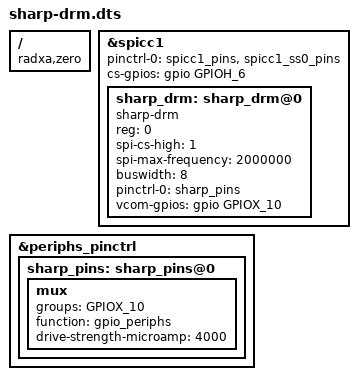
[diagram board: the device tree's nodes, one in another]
/dts-v1/;
/plugin/;

#include <dt-bindings/gpio/gpio.h>
#include <dt-bindings/gpio/meson-g12a-gpio.h>

/ {
    compatible = "radxa,zero", "radxa,zero2", "amlogic,g12a", "amlogic,g12b";

    fragment@0 {
        target = <&spicc1>;
        __overlay__ {
            #address-cells = <1>;
            #size-cells = <0>;

            pinctrl-0 = <&spicc1_pins &spicc1_ss0_pins>;
            pinctrl-names = "default";

            cs-gpios = <&gpio GPIOH_6 GPIO_ACTIVE_HIGH>;

            status = "okay";

            sharp_drm: sharp_drm@0 {
                compatible = "sharp-drm";
                reg = <0>;

                spi-cs-high = <1>;
                spi-max-frequency = <2000000>;

                buswidth = <8>;

                pinctrl-names = "default";
                pinctrl-0 = <&sharp_pins>;

                vcom-gpios = <&gpio GPIOX_10 GPIO_ACTIVE_HIGH>;
            };
        };
    };

    fragment@1 {
        target = <&periphs_pinctrl>;
        __overlay__ {
            sharp_pins: sharp_pins@0 {
                mux {
                    groups = "GPIOX_10";
                    function = "gpio_periphs";
                    drive-strength-microamp = <4000>;
                };
            };
        };
    };
};
